# M0519AE_v1 register map
File version: 1.0
Registers are 32-bit, read-write, reset 0x0 unless marked. A register's access mark holds for its fields unless they carry their own. Offsets are from the block's base; [hi:lo] are bit positions; {n}, {i} and the like mark numbered series; 'fields as' and 'values as' point back to an identical list.

## GPIO — GPIO Register Map
Base 0x50004000
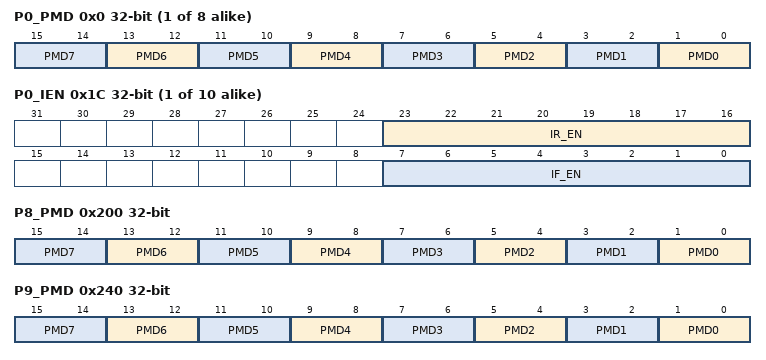
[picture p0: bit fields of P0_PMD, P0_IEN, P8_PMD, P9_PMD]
{0x0+0x40*i} P{i}_PMD (i=0..7) — GPIO Port {i} Pin I/O Mode Control
  [all] fields
    0=GPIO port [n] pin is in Input mode; 1=GPIO port [n] pin is in Push-pull Output mode; 2=GPIO port [n] pin is in Open-drain Output mode; 3=GPIO port [n] pin is in Quasi-bidirectional mode
  [2n+1:2n] PMD{n} (n=0..7) — Port 0-a I/O Pin[N] Mode Control. Determine each I/O mode of Px pins.
{0x4+0x40*i} P{i}_OFFD (i=0..9) — GPIO Port {i} Pin Digital Input Path Disable Control
  [23:16] OFFD — Port 0-a Pin[N] Digital Input Path Disable Control. Each of these bits is used to control if the digital input path of corresponding GPIO pin is disabled. If input is analog signal, users can disable GPIO digital input path to avoid input current leakage.
    0=I/O digital input path Enabled; 1=I/O digital input path Disabled (digital input tied to low)
{0x8+0x40*i} P{i}_DOUT reset 0xFF (i=0..9) — GPIO Port {i} Data Output Value
  [7:0] DOUT — Port 0-a Pin[N] Output Value. Each of these bits controls the status of a GPIO pin when the GPIO is configured as Push-pull output, Open-drain output or Quasi-bidirectional mode.
    0=GPIO port [0/1/2/3/4/5/6/7/8/9/A] Pin[n] will drive Low if the GPIO pin is configured as Push-pull output, Open-drain output or Quasi-bidirectional mode; 1=GPIO port [0/1/2/3/4/5/6/7/8/9/A] Pin[n] will drive High if the GPIO pin is configured as Push-pull output or Quasi-bidirectional mode
{0xC+0x40*i} P{i}_DMASK (i=0..9) — GPIO Port {i} Data Output Write Mask
  [7:0] DMASK — Port 0-a Data Output Write Mask. These bits are used to protect the corresponding register of Px_DOUT bit[n]. When set the DMASK bit[n] is set to 1, the corresponding Px_DOUT[n] bit is protected. If the write signal is masked, write data to the protect bit is ignored.
    0=Corresponding Px_DOUT[n] bit can be updated; 1=Corresponding Px_DOUT[n] bit protected
{0x10+0x40*i} P{i}_PIN ro (reset mask 0xFFFFFF00) (i=0..9) — GPIO Port {i} Pin Value
  [7:0] PIN — Port 0-a Pin Values. Each bit of the register reflects the actual status of the respective GPIO pin. If the bit is 1, it indicates the corresponding pin status is high, else the pin status is low.
{0x14+0x40*i} P{i}_DBEN (i=0..9) — GPIO Port {i} De-bounce Enable
  [7:0] DBEN — Port 0-a Input Signal De-bounce Enable Bits. DBEN[n] is used to enable the de-bounce function for each corresponding bit. If the input signal pulse width cannot be sampled by continuous two de-bounce sample cycle, the input signal transition is seen as the signal bounce and will not trigger the interrupt. The de-bounce clock source is controlled by DBCLKSRC (DBNCECON[4]), one de-bounce sample cycle period is controlled by DBCLKSEL (DBNCECON[3:0]).
    0=Bit[n] de-bounce function Disabled; 1=Bit[n] de-bounce function Enabled
{0x18+0x40*i} P{i}_IMD (i=0..9) — GPIO Port {i} Interrupt Mode Control
  [7:0] IMD — Port 0-a Edge or Level Detection Interrupt Control. IMD[n] decides the pin interrupt triggered by level or edge. If the interrupt is by edge trigger, the trigger source can be controlled by de-bounce. If the interrupt is by level trigger, the input source is sampled by one HCLK clock and generates the interrupt.
    0=Edge triggered interrupt; 1=Level triggered interrupt
{0x1C+0x40*i} P{i}_IEN (i=0..9) — GPIO Port {i} Interrupt Enable
  [23:16] IR_EN — Port 0-a Interrupt Enable by Input Rising Edge or Input Level High. IR_EN[n] used to enable the interrupt for each of the corresponding input Px_PIN[n]. Set bit to 1 also enable the pin wake-up function. When setting the IR_EN[n] bit to 1: If the interrupt is level trigger, the input PIN[n] state at level "high" will generate the interrupt. If the interrupt is edge trigger, the input PIN[n] state change from "low-to-high" will generate the interrupt.
    0=PIN[n] level-high or low-to-high interrupt Disabled; 1=PIN[n] level-high or low-to-high interrupt Enabled
  [7:0] IF_EN — Port 0-a Interrupt Enable by Input Falling Edge or Input Level Low. IF_EN[n] is used to enable the interrupt for each of the corresponding input Px_PIN[n]. Set bit to 1 also enable the pin wake-up function. When setting the IF_EN[n] bit to 1: If the interrupt is level trigger, the input PIN[n] state at level "low" will generate the interrupt. If the interrupt is edge trigger, the input PIN[n] state change from "high-to-low" will generate the interrupt.
    0=PIN[n] state low-level or high-to-low change interrupt Disabled; 1=PIN[n] state low-level or high-to-low change interrupt Enabled
{0x20+0x40*i} P{i}_ISF reset not defined (i=0..5) — GPIO Port {i} Interrupt Source Flag
  [7:0] IF_ISF — Port 0-a Interrupt Source Flag. These bits are edge/level trigger event indicators of each pin of Port x, if GPG0_INT or GPG1_INT enable bit is set, the corresponding interrupt service routine will be served. Note that P3.2 and P3.3 will only vector to INT0_INT and INT1_INT ISRs if its own interrupt is enabled. Read :
    0=No interrupt at Px[n]. No action; 1=Px[n] generates an interrupt. Clear the corresponding pending interrupt
{0x20+0x40*i} P{i}_ISF reset not defined (i=7..9) — GPIO Port {i} Interrupt Source Flag
  fields as P0_ISF
0x200 P6_ISF reset not defined — GPIO Port 6 Interrupt Source Flag
  fields as P0_ISF
0x200 P8_PMD (alternate view of P6_ISF) — GPIO Port 8 Pin I/O Mode Control
  fields as P0_PMD
0x240 P9_PMD — GPIO Port 9 Pin I/O Mode Control
  fields as P0_PMD
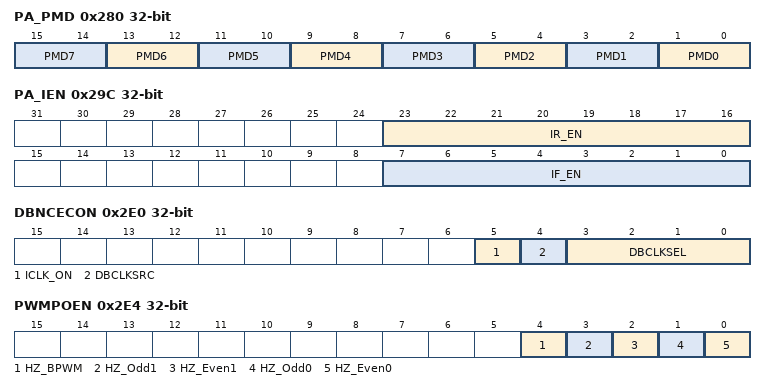
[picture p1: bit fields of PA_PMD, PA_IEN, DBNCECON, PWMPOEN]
0x280 PA_PMD — GPIO Port A Pin I/O Mode Control
  fields as P0_PMD
0x284 PA_OFFD — GPIO Port A Pin Digital Input Path Disable Control
  fields as P0_OFFD
0x288 PA_DOUT reset 0xFF — GPIO Port A Data Output Value
  fields as P0_DOUT
0x28C PA_DMASK — GPIO Port A Data Output Write Mask
  fields as P0_DMASK
0x290 PA_PIN ro (reset mask 0xFFFFFF00) — GPIO Port A Pin Value
  fields as P0_PIN
0x294 PA_DBEN — GPIO Port A De-bounce Enable
  fields as P0_DBEN
0x298 PA_IMD — GPIO Port A Interrupt Mode Control
  fields as P0_IMD
0x29C PA_IEN — GPIO Port A Interrupt Enable
  fields as P0_IEN
0x2A0 PA_ISF reset not defined — GPIO Port A Interrupt Source Flag
  fields as P0_ISF
0x2E0 DBNCECON — External Interrupt De-bounce Control
  [5] ICLK_ON — Interrupt Clock on Mode. It is recommended to turn off this bit to save system power if no special application concern.
    0=Edge detection circuit is active only if I/O pin corresponding Px_IEN bit is set to 1; 1=All I/O pins edge detection circuit is always active after reset
  [4] DBCLKSRC — De-bounce Counter Clock Source Selection
    0=De-bounce counter clock source is the HCLK; 1=De-bounce counter clock source is the internal 10 kHz low speed oscillator
  [3:0] DBCLKSEL — De-bounce Sampling Cycle Selection
    0=Sample interrupt input once per 1 clocks; 1=Sample interrupt input once per 2 clocks; 2=Sample interrupt input once per 4 clocks; 3=Sample interrupt input once per 8 clocks; 4=Sample interrupt input once per 16 clocks; 5=Sample interrupt input once per 32 clocks; 6=Sample interrupt input once per 64 clocks; 7=Sample interrupt input once per 128 clocks; 8=Sample interrupt input once per 256 clocks; 9=Sample interrupt input once per 2*256 clocks; 10=Sample interrupt input once per 4*256 clocks; 11=Sample interrupt input once per 8*256 clocks; 12=Sample interrupt input once per 16*256 clocks; 13=Sample interrupt input once per 32*256 clocks; 14=Sample interrupt input once per 64*256 clocks; 15=Sample interrupt input once per 128*256 clocks
0x2E4 PWMPOEN (reset mask 0xFFFFFF00) — PWM Port Output Enable
  [4] HZ_BPWM — Basic PWM0 Ports Output Control. Note: The initial value is loaded from CHZ_BPWM (Config0[12]) after any reset.
    0=The driving mode of Basic PWM ports are controlled by GPIO mode register; 1=The driving mode of Basic PWM ports are forced in tri-state (Hi-Z) all the time
  [3] HZ_Odd1 — Enhanced PWM Unit1 Odd Ports Output Control. Note: The initial value is loaded from CHZ_Odd1 (Config0[11]) after any reset.
    0=The driving mode of Enhanced PWM unit1 odd ports are controlled by GPIO mode register (Px_PMD) or multi-function register (Px_MFP); 1=The driving mode of Enhanced PWM unit1 odd ports are forced in tri-state (Hi-Z) all the time
  [2] HZ_Even1 — Enhanced PWM Unit1 Even Ports Output Control. Note: The initial value is loaded from CHZ_Even1 (Config0[10]) after any reset.
    0=The driving mode of Enhanced PWM unit1 even ports are controlled by GPIO mode register (Px_PMD) or multi-function register (Px_MFP); 1=The driving mode of Enhanced PWM unit1 even ports are forced in tri-state (Hi-Z) all the time
  [1] HZ_Odd0 — Enhanced PWM Unit0 Odd Ports Output Control. Note: The initial value is loaded from CHZ_Odd0 (Config0[9]) after any reset.
    0=The driving mode of Enhanced PWM unit0 odd ports are controlled by GPIO mode register (Px_PMD) or multi-function register (Px_MFP); 1=The driving mode of Enhanced PWM unit0 odd ports are forced in tri-state (Hi-Z) all the time
  [0] HZ_Even0 — Enhanced PWM Unit0 Even Ports Output Control. Note: The initial value is loaded from CHZ_Even0 (Config0[8]) after any reset.
    0=The driving mode of Enhanced PWM unit0 even ports are controlled by GPIO mode register (Px_PMD) or multi-function register (Px_MFP); 1=The driving mode of Enhanced PWM unit0 even ports are forced in tri-state (Hi-Z) all the time
{0x300+0x20*i} P{i}_0 (reset mask 0xFFFFFFF0) (i=0..9) — GPIO P{i}.n Pin Data Input/Output
  [0] Pxn — GPIO Px.N Pin Data Input/Output. Write this bit can control one GPIO pin output value. Read this register to get GPIO pin status. For example: writing P0_0 will reflect the written value to bit P0_DOUT[0], read P0_0 will return the value of P0_PIN[0]. Note: The write operation will not be affected by register Px_DMASK.
    0=Corresponding GPIO pin set to low; 1=Corresponding GPIO pin set to high
{0x304+0x20*i} P{i}_1 (reset mask 0xFFFFFFF0) (i=0..9) — GPIO P{i}.n Pin Data Input/Output
  fields as P0_0
{0x308+0x20*i} P{i}_2 (reset mask 0xFFFFFFF0) (i=0..9) — GPIO P{i}.n Pin Data Input/Output
  fields as P0_0
{0x30C+0x20*i} P{i}_3 (reset mask 0xFFFFFFF0) (i=0..9) — GPIO P{i}.n Pin Data Input/Output
  fields as P0_0
{0x310+0x20*i} P{i}_4 (reset mask 0xFFFFFFF0) (i=0..9) — GPIO P{i}.n Pin Data Input/Output
  fields as P0_0
{0x314+0x20*i} P{i}_5 (reset mask 0xFFFFFFF0) (i=0..9) — GPIO P{i}.n Pin Data Input/Output
  fields as P0_0
{0x318+0x20*i} P{i}_6 (reset mask 0xFFFFFFF0) (i=0..9) — GPIO P{i}.n Pin Data Input/Output
  fields as P0_0
{0x31C+0x20*i} P{i}_7 (reset mask 0xFFFFFFF0) (i=0..9) — GPIO P{i}.n Pin Data Input/Output
  fields as P0_0
0x440 PA_0 (reset mask 0xFFFFFFF0) — GPIO PA.n Pin Data Input/Output
  fields as P0_0
0x444 PA_1 (reset mask 0xFFFFFFF0) — GPIO PA.n Pin Data Input/Output
  fields as P0_0
